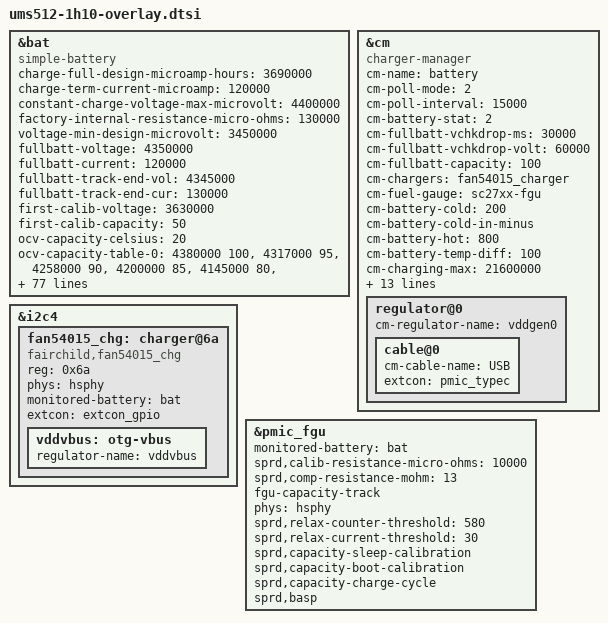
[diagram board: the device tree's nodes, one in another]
&bat {
	compatible = "simple-battery";
	status = "okay";
	charge-full-design-microamp-hours = <3690000>;
	charge-term-current-microamp = <120000>;
	constant-charge-voltage-max-microvolt = <4400000>;
	factory-internal-resistance-micro-ohms = <130000>;
	voltage-min-design-microvolt = <3450000>;
	fullbatt-voltage = <4350000>;
	fullbatt-current = <120000>;
	fullbatt-track-end-vol = <4345000>;
	fullbatt-track-end-cur = <130000>;
	first-calib-voltage = <3630000>;
	first-calib-capacity = <50>;

	ocv-capacity-celsius = <20>;
	ocv-capacity-table-0 = <4380000 100>, <4317000 95>, <4258000 90>,
				<4200000 85>, <4145000 80>, <4092000 75>,
				<4047000 70>, <3990000 65>, <3955000 60>,
				<3900000 55>, <3861000 50>, <3834000 45>,
				<3813000 40>, <3796000 35>, <3783000 30>,
				<3770000 25>, <3752000 20>, <3730000 15>,
				<3698000 10>, <3687000 5>, <3400000 0>;
	voltage-temp-table = <1110270 800>, <999440 850>, <890430 900>,
				<785590 950>, <687630 1000>, <598220 1050>,
				<517680 1100>, <446100 1150>, <383390 1200>,
				<328950 1250>, <281840 1300>, <241480 1350>,
				<207030 1400>, <177580 1450>, <152490 1500>,
				<131160 1550>, <113000 1600>, <97790 1650>;
	capacity-temp-table = <45 100>, <25 100>, <10 98>, <0 93>, <(-10) 85>, <(-20) 64>;
	resistance-temp-table = <45 77>, <25 100>, <10 546>, <0 769>, <(-10) 892>, <(-20) 923>;

	battery-internal-resistance-celsius = <(-20)>, <(-10)>, <0>, <10>,
		<25>, <35>, <45>, <55>;
	battery-internal-resistance-table-0 = <1224>, <1224>, <1140>,
		<1084>, <1034>, <1001>, <994>, <992>, <992>, <992>,
		<996>, <1002>, <1010>, <1024>, <1045>, <1072>, <1180>,
		<1393>, <1756>, <2461>, <4272>;
	battery-internal-resistance-table-1 = <893>, <893>, <818>, <767>,
		<743>, <705>, <685>, <684>, <678>, <675>, <672>, <673>,
		<679>, <691>, <709>, <734>, <765>, <799>, <839>, <899>,
		<1092>;
	battery-internal-resistance-table-2 = <407>, <407>, <402>, <423>,
		<429>, <428>, <409>, <416>, <408>, <395>, <390>, <390>,
		<393>, <398>, <405>, <416>, <431>, <452>, <492>, <585>,
		<730>;
	battery-internal-resistance-table-3 = <381>, <381>, <378>, <371>,
		<366>, <374>, <358>, <364>, <349>, <332>, <327>, <329>,
		<334>, <340>, <350>, <366>, <386>, <417>, <475>, <585>,
		<771>;
	battery-internal-resistance-table-4 = <182>, <182>, <179>, <179>,
		<179>, <181>, <182>, <195>, <194>, <173>, <164>, <164>,
		<167>, <171>, <175>, <174>, <172>, <179>, <187>, <244>,
		<311>;
	battery-internal-resistance-table-5 = <168>, <168>, <175>, <172>,
		<171>, <171>, <173>, <184>, <176>, <153>, <147>, <147>,
		<150>, <153>, <156>, <152>, <149>, <154>, <158>, <206>,
		<255>;
	battery-internal-resistance-table-6 = <123>, <123>, <122>, <122>,
		<123>, <126>, <130>, <138>, <143>, <120>, <115>, <116>,
		<119>, <124>, <129>, <120>, <117>, <119>, <117>, <139>,
		<156>;
	battery-internal-resistance-table-7 = <106>, <106>, <106>, <106>,
		<108>, <110>, <113>, <119>, <128>, <107>, <104>, <105>,
		<108>, <112>, <117>, <107>, <106>, <107>, <105>, <127>,
		<140>;
	battery-internal-resistance-ocv-table = <4339000>, <4276000>,
		<4221000>, <4169000>, <4118000>, <4072000>, <4022000>,
		<3983000>, <3942000>, <3892000>, <3857000>, <3833000>,
		<3813000>, <3797000>, <3783000>, <3766000>, <3746000>,
		<3723000>, <3693000>, <3680000>, <3439000>;

	charge-sdp-current-microamp = <500000 500000>;
	charge-dcp-current-microamp = <1150000 3000000>;
	charge-cdp-current-microamp = <1150000 1150000>;
	charge-unknown-current-microamp = <500000 500000>;

	dcp-jeita-temp-table = <1000 1030 0 4400000>, <1150 1180 700000 4400000>,
		<1450 1420 1150000 4400000>, <1600 1570 700000 4100000>;
	sdp-jeita-temp-table = <1000 1030 0 4400000>, <1150 1180 500000 4400000>,
		<1450 1420 500000 4400000>, <1600 1570 500000 4100000>;
	cdp-jeita-temp-table = <1000 1030 0 4400000>, <1150 1180 700000 4400000>,
		<1450 1420 1150000 4400000>, <1600 1570 700000 4100000>;
	unknown-jeita-temp-table = <1000 1030 0 4400000>, <1150 1180 500000 4400000>,
		<1450 1420 500000 4400000>, <1600 1570 500000 4100000>;
	force-jeita-status = <2>;
};

&cm {
	compatible = "charger-manager";
	status = "okay";
	cm-name = "battery";
	cm-poll-mode = <2>;
	cm-poll-interval = <15000>;
	cm-battery-stat = <2>;

	cm-fullbatt-vchkdrop-ms = <30000>;
	cm-fullbatt-vchkdrop-volt = <60000>;
	cm-fullbatt-capacity = <100>;

	cm-chargers = "fan54015_charger";
	cm-fuel-gauge = "sc27xx-fgu";

	/* in deci centigrade */
	cm-battery-cold = <200>;
	cm-battery-cold-in-minus;
	cm-battery-hot = <800>;
	cm-battery-temp-diff = <100>;

	/* Allow charging for 6hr */
	cm-charging-max = <21600000>;
	/* recovery charging after stop charging 45min */
	cm-discharging-max = <2700000>;

	/* the interval to feed charger watchdog */
	cm-wdt-interval = <60>;

	/* drop voltage in microVolts to allow shutdown */
	cm-shutdown-voltage = <3100000>;

	/* when 99% of the time is exceeded, it will be forced to 100% */
	cm-tickle-time-out = <1500>;

	/* how much time to allow capacity change */
	cm-one-cap-time = <30>;
	cm-thermal-zone = "board-thmzone";
	/* when the safe charging voltage is exceeded, stop charging */
	cm-charge-voltage-max = <6500000>;
	/* drop voltage in microVolts to restart charging */
	cm-charge-voltage-drop = <700000>;

	monitored-battery = <&bat>;
	cm-keep-awake;

	cm-cap-remap-table = <1 2 3>, <2 3 2>, <98 99 2>, <99 100 3>;

	phys = <&hsphy>;

	regulator@0 {
		cm-regulator-name = "vddgen0";
		cable@0 {
			cm-cable-name = "USB";
			extcon = <&pmic_typec>;
		};
	};
};

&i2c4 {
	#address-cells = <1>;
	#size-cells = <0>;

	status = "okay";
	fan54015_chg: charger@6a {
		compatible = "fairchild,fan54015_chg";
		reg = <0x6a>;
		phys = <&hsphy>;
		monitored-battery = <&bat>;
		extcon = <&extcon_gpio>;
		vddvbus:otg-vbus {
			regulator-name = "vddvbus";
		};
	};
};

&pmic_fgu {
	monitored-battery = <&bat>;
	sprd,calib-resistance-micro-ohms = <10000>;
	sprd,comp-resistance-mohm = <13>;

	fgu-capacity-track;
	phys = <&hsphy>;

	sprd,relax-counter-threshold = <580>;
	sprd,relax-current-threshold = <30>;
	sprd,capacity-sleep-calibration;

	sprd,capacity-boot-calibration;
	sprd,capacity-charge-cycle;
	sprd,basp;
};
